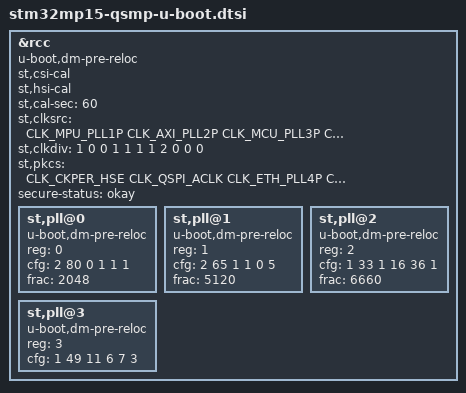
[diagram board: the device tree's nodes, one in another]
// SPDX-License-Identifier: GPL-2.0 OR BSD-3-Clause
/*
 * Copyright (C) 2020: Lothar Waßmann <LW@KARO-electronics.de>
 */

&rcc {
	u-boot,dm-pre-reloc;
	st,csi-cal;
	st,hsi-cal;
	st,cal-sec = <60>;
	st,clksrc = <
		CLK_MPU_PLL1P
		CLK_AXI_PLL2P
		CLK_MCU_PLL3P
		CLK_PLL12_HSE
		CLK_PLL3_HSE
		CLK_PLL4_HSE
		CLK_RTC_LSI
		CLK_MCO1_DISABLED
		CLK_MCO2_DISABLED
	>;
	st,clkdiv = <
		1	/* MPU */
		0	/* AXI */
		0	/* MCU */
		1	/* APB1 */
		1	/* APB2 */
		1	/* APB3 */
		1	/* APB4 */
		2	/* APB5 */
		0	/* RTC */
		0	/* MCO1 */
		0	/* MCO2 */
	>;
	st,pkcs = <
		CLK_CKPER_HSE
		CLK_QSPI_ACLK
		CLK_ETH_PLL4P
		CLK_SDMMC12_HCLK6
		CLK_STGEN_HSI
		CLK_USBPHY_HSE
		CLK_SPI2S1_DISABLED
		CLK_SPI2S23_DISABLED
		CLK_SPI45_HSI
		CLK_SPI6_HSI
		CLK_I2C46_PCLK5
		CLK_SDMMC3_DISABLED
		CLK_USBO_USBPHY
		CLK_ADC_CKPER
		CLK_CEC_DISABLED
		CLK_I2C12_PCLK1
		CLK_I2C35_PCLK1
		CLK_UART1_DISABLED
		CLK_UART24_HSI
		CLK_UART35_HSI
		CLK_UART6_DISABLED
		CLK_UART78_DISABLED
		CLK_SPDIF_DISABLED
		CLK_FDCAN_HSE
		CLK_SAI1_DISABLED
		CLK_SAI2_PLL4Q
		CLK_SAI3_DISABLED
		CLK_SAI4_DISABLED
		CLK_LPTIM1_PCLK1
		CLK_LPTIM23_DISABLED
		CLK_LPTIM45_DISABLED
		CLK_RNG1_LSI
	>;
	#address-cells = <1>;
	#size-cells = <0>;
	secure-status = "okay";

	st,pll@0 {
		u-boot,dm-pre-reloc;
		reg = <0>;
		cfg = <2 80 0 1 1 1>;
		frac = <2048>;
	};

	st,pll@1 {
		u-boot,dm-pre-reloc;
		reg = <1>;
		cfg = <2 65 1 1 0 5>;
		frac = <5120>;
	};

	st,pll@2 {
		u-boot,dm-pre-reloc;
		reg = <2>;
		cfg = <1 33 1 16 36 1>;
		frac = <6660>;
	};

	st,pll@3 {
		u-boot,dm-pre-reloc;
		reg = <3>;
		cfg = <1 49 11 6 7 3>;
	};
};
